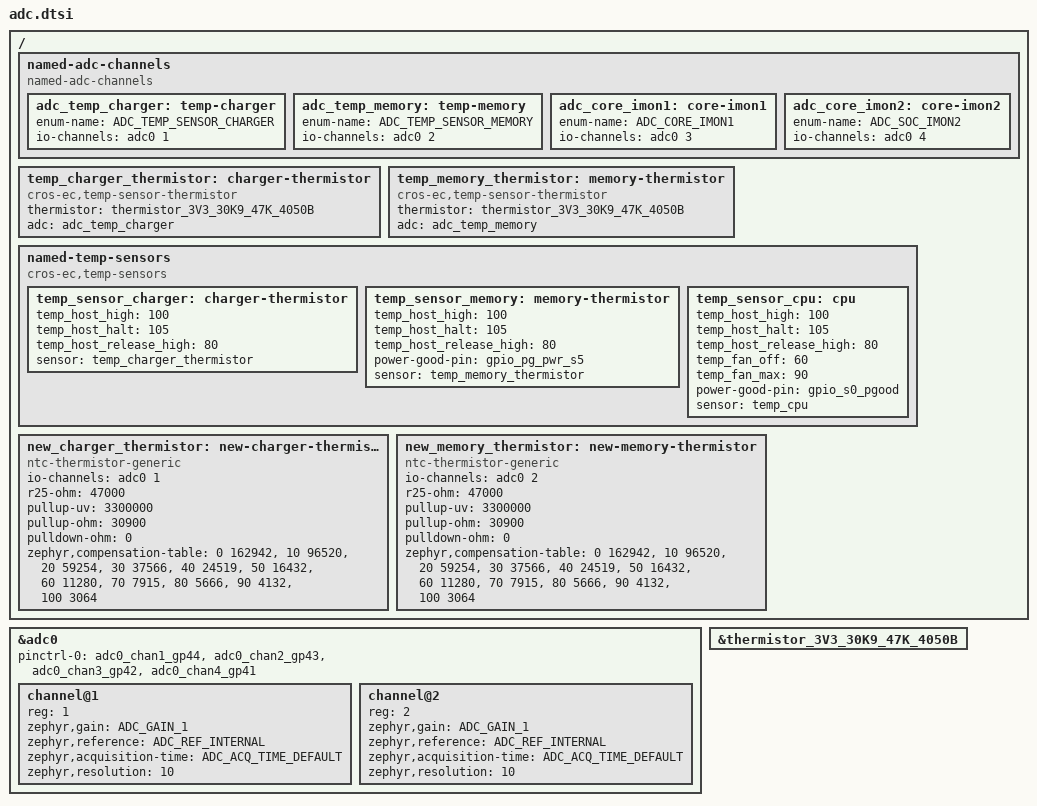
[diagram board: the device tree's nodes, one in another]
/* Copyright 2021 The ChromiumOS Authors
 * Use of this source code is governed by a BSD-style license that can be
 * found in the LICENSE file.
 */

#include <cros/thermistor/thermistor.dtsi>

/ {
	named-adc-channels {
		compatible = "named-adc-channels";

		adc_temp_charger: temp-charger {
			enum-name = "ADC_TEMP_SENSOR_CHARGER";
			io-channels = <&adc0 1>;
		};
		adc_temp_memory: temp-memory {
			enum-name = "ADC_TEMP_SENSOR_MEMORY";
			io-channels = <&adc0 2>;
		};
		adc_core_imon1: core-imon1 {
			enum-name = "ADC_CORE_IMON1";
			io-channels = <&adc0 3>;
		};
		adc_core_imon2: core-imon2 {
			enum-name = "ADC_SOC_IMON2";
			io-channels = <&adc0 4>;
		};
	};

	temp_charger_thermistor: charger-thermistor {
		compatible = "cros-ec,temp-sensor-thermistor";
		thermistor = <&thermistor_3V3_30K9_47K_4050B>;
		adc = <&adc_temp_charger>;
	};

	temp_memory_thermistor: memory-thermistor {
		compatible = "cros-ec,temp-sensor-thermistor";
		thermistor = <&thermistor_3V3_30K9_47K_4050B>;
		adc = <&adc_temp_memory>;
	};

	named-temp-sensors {
		compatible = "cros-ec,temp-sensors";
		temp_sensor_charger: charger-thermistor {
			temp_host_high = <100>;
			temp_host_halt = <105>;
			temp_host_release_high = <80>;
			sensor = <&temp_charger_thermistor>;
		};

		temp_sensor_memory: memory-thermistor {
			temp_host_high = <100>;
			temp_host_halt = <105>;
			temp_host_release_high = <80>;
			power-good-pin = <&gpio_pg_pwr_s5>;
			sensor = <&temp_memory_thermistor>;
		};

		temp_sensor_cpu: cpu {
			temp_host_high = <100>;
			temp_host_halt = <105>;
			temp_host_release_high = <80>;
			temp_fan_off = <60>;
			temp_fan_max = <90>;
			power-good-pin = <&gpio_s0_pgood>;
			sensor = <&temp_cpu>;
		};
	};

	/* B = 4050, R0 = 30900 */
	new_charger_thermistor: new-charger-thermistor {
		compatible = "ntc-thermistor-generic";
		io-channels = <&adc0 1>;
		r25-ohm = <47000>;
		pullup-uv = <3300000>;
		pullup-ohm = <30900>;
		pulldown-ohm = <0>;
		zephyr,compensation-table =
			<0 162942>,
			<10 96520>,
			<20 59254>,
			<30 37566>,
			<40 24519>,
			<50 16432>,
			<60 11280>,
			<70 7915>,
			<80 5666>,
			<90 4132>,
			<100 3064>;
	};

	/* B = 4050, R0 = 30900 */
	new_memory_thermistor: new-memory-thermistor {
		compatible = "ntc-thermistor-generic";
		io-channels = <&adc0 2>;
		r25-ohm = <47000>;
		pullup-uv = <3300000>;
		pullup-ohm = <30900>;
		pulldown-ohm = <0>;
		zephyr,compensation-table =
			<0 162942>,
			<10 96520>,
			<20 59254>,
			<30 37566>,
			<40 24519>,
			<50 16432>,
			<60 11280>,
			<70 7915>,
			<80 5666>,
			<90 4132>,
			<100 3064>;
	};
};

&adc0 {
	#address-cells = <1>;
	#size-cells = <0>;

	status = "okay";
	pinctrl-0 = <&adc0_chan1_gp44
		     &adc0_chan2_gp43
		     &adc0_chan3_gp42
		     &adc0_chan4_gp41>;
	pinctrl-names = "default";

	channel@1 {
		reg = <1>;
		zephyr,gain = "ADC_GAIN_1";
		zephyr,reference = "ADC_REF_INTERNAL";
		zephyr,acquisition-time = <ADC_ACQ_TIME_DEFAULT>;
		zephyr,resolution = <10>;
	};

	channel@2 {
		reg = <2>;
		zephyr,gain = "ADC_GAIN_1";
		zephyr,reference = "ADC_REF_INTERNAL";
		zephyr,acquisition-time = <ADC_ACQ_TIME_DEFAULT>;
		zephyr,resolution = <10>;
	};
};

&thermistor_3V3_30K9_47K_4050B {
	status = "okay";
};
